# TM4C129ENCPDT register map
File version: 1.0
CPU: CORTEX_M4 1.0, other endian, MPU, FPU, 3 interrupt priority bits
Registers are 32-bit, read-write, reset 0x0 unless marked. A register's access mark holds for its fields unless they carry their own. Offsets are from the block's base; [hi:lo] are bit positions; <NAME> marks a mode.

## UART0 — UART register offsets
Base 0x4000C000
Same registers: UART1 0x4000D000, UART2 0x4000E000, UART3 0x4000F000, UART4 0x40010000, UART5 0x40011000, UART6 0x40012000, UART7 0x40013000
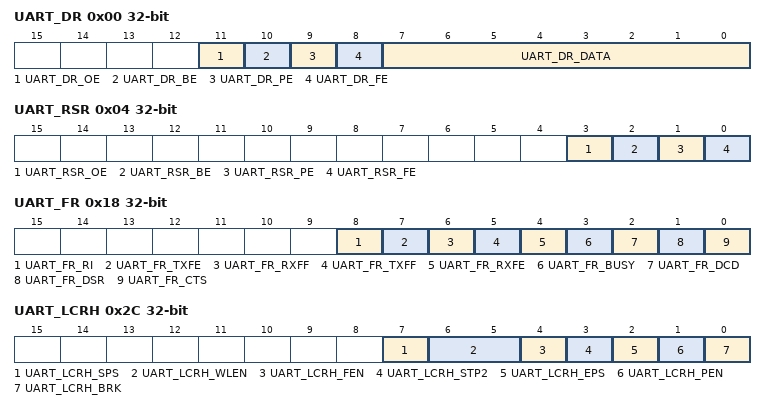
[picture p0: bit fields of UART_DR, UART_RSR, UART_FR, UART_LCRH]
0x00 UART_DR — UART Data
  [11] UART_DR_OE — [11:11] UART Overrun Error
  [10] UART_DR_BE — [10:10] UART Break Error
  [9] UART_DR_PE — [9:9] UART Parity Error
  [8] UART_DR_FE — [8:8] UART Framing Error
  [7:0] UART_DR_DATA — [7:0] Data Transmitted or Received
0x04 UART_RSR — UART Receive Status/Error Clear
  [3] UART_RSR_OE — [3:3] UART Overrun Error
  [2] UART_RSR_BE — [2:2] UART Break Error
  [1] UART_RSR_PE — [1:1] UART Parity Error
  [0] UART_RSR_FE — [0:0] UART Framing Error
0x04 UART_ECR — UART Receive Status/Error Clear
  [7:0] UART_ECR_DATA — [7:0] Error Clear
0x18 UART_FR — UART Flag
  [8] UART_FR_RI — [8:8] Ring Indicator
  [7] UART_FR_TXFE — [7:7] UART Transmit FIFO Empty
  [6] UART_FR_RXFF — [6:6] UART Receive FIFO Full
  [5] UART_FR_TXFF — [5:5] UART Transmit FIFO Full
  [4] UART_FR_RXFE — [4:4] UART Receive FIFO Empty
  [3] UART_FR_BUSY — [3:3] UART Busy
  [2] UART_FR_DCD — [2:2] Data Carrier Detect
  [1] UART_FR_DSR — [1:1] Data Set Ready
  [0] UART_FR_CTS — [0:0] Clear To Send
0x20 UART_ILPR — UART IrDA Low-Power Register
  [7:0] UART_ILPR_ILPDVSR — [7:0] IrDA Low-Power Divisor
0x24 UART_IBRD — UART Integer Baud-Rate Divisor
  [15:0] UART_IBRD_DIVINT — [15:0] Integer Baud-Rate Divisor
0x28 UART_FBRD — UART Fractional Baud-Rate Divisor
  [5:0] UART_FBRD_DIVFRAC — [5:0] Fractional Baud-Rate Divisor
0x2C UART_LCRH — UART Line Control
  [7] UART_LCRH_SPS — [7:7] UART Stick Parity Select
  [6:5] UART_LCRH_WLEN — [6:5] UART Word Length
    0=5 bits (default); 32=6 bits; 64=7 bits; 96=8 bits
  [4] UART_LCRH_FEN — [4:4] UART Enable FIFOs
  [3] UART_LCRH_STP2 — [3:3] UART Two Stop Bits Select
  [2] UART_LCRH_EPS — [2:2] UART Even Parity Select
  [1] UART_LCRH_PEN — [1:1] UART Parity Enable
  [0] UART_LCRH_BRK — [0:0] UART Send Break
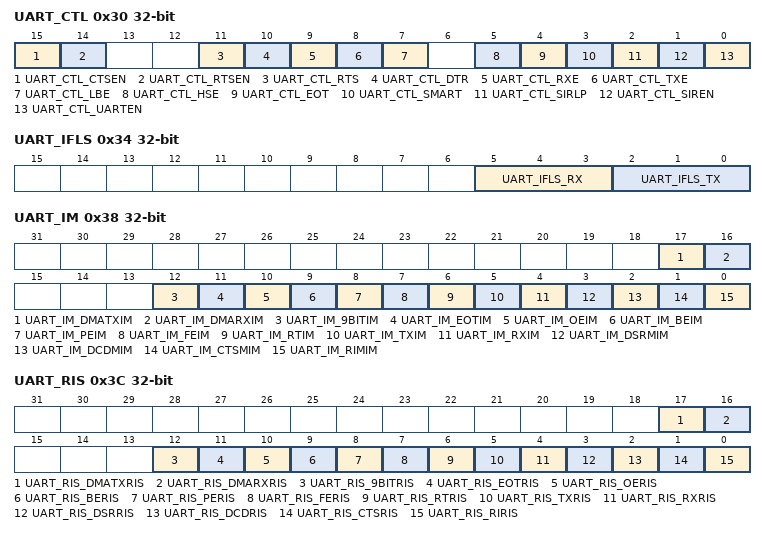
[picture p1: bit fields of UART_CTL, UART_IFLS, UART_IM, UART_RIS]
0x30 UART_CTL — UART Control
  [15] UART_CTL_CTSEN — [15:15] Enable Clear To Send
  [14] UART_CTL_RTSEN — [14:14] Enable Request to Send
  [11] UART_CTL_RTS — [11:11] Request to Send
  [10] UART_CTL_DTR — [10:10] Data Terminal Ready
  [9] UART_CTL_RXE — [9:9] UART Receive Enable
  [8] UART_CTL_TXE — [8:8] UART Transmit Enable
  [7] UART_CTL_LBE — [7:7] UART Loop Back Enable
  [5] UART_CTL_HSE — [5:5] High-Speed Enable
  [4] UART_CTL_EOT — [4:4] End of Transmission
  [3] UART_CTL_SMART — [3:3] ISO 7816 Smart Card Support
  [2] UART_CTL_SIRLP — [2:2] UART SIR Low-Power Mode
  [1] UART_CTL_SIREN — [1:1] UART SIR Enable
  [0] UART_CTL_UARTEN — [0:0] UART Enable
0x34 UART_IFLS — UART Interrupt FIFO Level Select
  [5:3] UART_IFLS_RX — [5:3] UART Receive Interrupt FIFO Level Select
    0=UART_IFLS_RX1_8 (RX FIFO >= 1/8 full); 8=UART_IFLS_RX2_8 (RX FIFO >= 1/4 full); 16=UART_IFLS_RX4_8 (RX FIFO >= 1/2 full (default)); 24=UART_IFLS_RX6_8 (RX FIFO >= 3/4 full); 32=UART_IFLS_RX7_8 (RX FIFO >= 7/8 full)
  [2:0] UART_IFLS_TX — [2:0] UART Transmit Interrupt FIFO Level Select
    0=UART_IFLS_TX1_8 (TX FIFO <= 1/8 full); 1=UART_IFLS_TX2_8 (TX FIFO <= 1/4 full); 2=UART_IFLS_TX4_8 (TX FIFO <= 1/2 full (default)); 3=UART_IFLS_TX6_8 (TX FIFO <= 3/4 full); 4=UART_IFLS_TX7_8 (TX FIFO <= 7/8 full)
0x38 UART_IM — UART Interrupt Mask
  [17] UART_IM_DMATXIM — [17:17] Transmit DMA Interrupt Mask
  [16] UART_IM_DMARXIM — [16:16] Receive DMA Interrupt Mask
  [12] UART_IM_9BITIM — [12:12] 9-Bit Mode Interrupt Mask
  [11] UART_IM_EOTIM — [11:11] End of Transmission Interrupt Mask
  [10] UART_IM_OEIM — [10:10] UART Overrun Error Interrupt Mask
  [9] UART_IM_BEIM — [9:9] UART Break Error Interrupt Mask
  [8] UART_IM_PEIM — [8:8] UART Parity Error Interrupt Mask
  [7] UART_IM_FEIM — [7:7] UART Framing Error Interrupt Mask
  [6] UART_IM_RTIM — [6:6] UART Receive Time-Out Interrupt Mask
  [5] UART_IM_TXIM — [5:5] UART Transmit Interrupt Mask
  [4] UART_IM_RXIM — [4:4] UART Receive Interrupt Mask
  [3] UART_IM_DSRMIM — [3:3] UART Data Set Ready Modem Interrupt Mask
  [2] UART_IM_DCDMIM — [2:2] UART Data Carrier Detect Modem Interrupt Mask
  [1] UART_IM_CTSMIM — [1:1] UART Clear to Send Modem Interrupt Mask
  [0] UART_IM_RIMIM — [0:0] UART Ring Indicator Modem Interrupt Mask
0x3C UART_RIS — UART Raw Interrupt Status
  [17] UART_RIS_DMATXRIS — [17:17] Transmit DMA Raw Interrupt Status
  [16] UART_RIS_DMARXRIS — [16:16] Receive DMA Raw Interrupt Status
  [12] UART_RIS_9BITRIS — [12:12] 9-Bit Mode Raw Interrupt Status
  [11] UART_RIS_EOTRIS — [11:11] End of Transmission Raw Interrupt Status
  [10] UART_RIS_OERIS — [10:10] UART Overrun Error Raw Interrupt Status
  [9] UART_RIS_BERIS — [9:9] UART Break Error Raw Interrupt Status
  [8] UART_RIS_PERIS — [8:8] UART Parity Error Raw Interrupt Status
  [7] UART_RIS_FERIS — [7:7] UART Framing Error Raw Interrupt Status
  [6] UART_RIS_RTRIS — [6:6] UART Receive Time-Out Raw Interrupt Status
  [5] UART_RIS_TXRIS — [5:5] UART Transmit Raw Interrupt Status
  [4] UART_RIS_RXRIS — [4:4] UART Receive Raw Interrupt Status
  [3] UART_RIS_DSRRIS — [3:3] UART Data Set Ready Modem Raw Interrupt Status
  [2] UART_RIS_DCDRIS — [2:2] UART Data Carrier Detect Modem Raw Interrupt Status
  [1] UART_RIS_CTSRIS — [1:1] UART Clear to Send Modem Raw Interrupt Status
  [0] UART_RIS_RIRIS — [0:0] UART Ring Indicator Modem Raw Interrupt Status
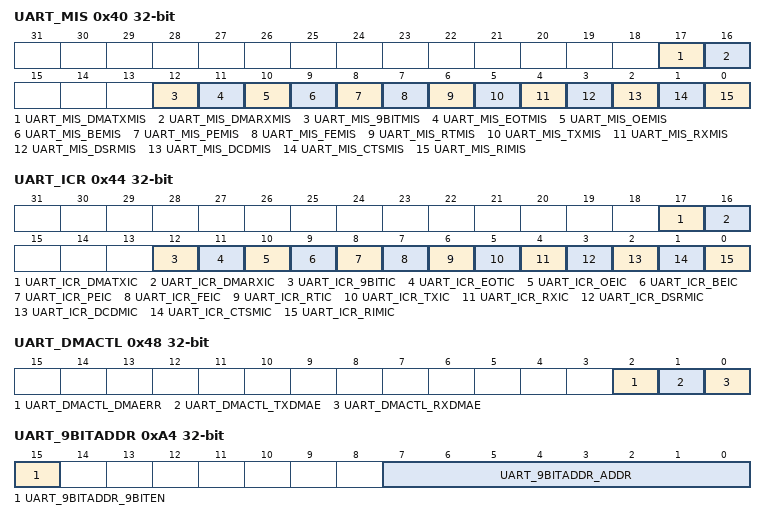
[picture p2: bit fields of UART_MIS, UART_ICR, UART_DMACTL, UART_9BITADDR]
0x40 UART_MIS — UART Masked Interrupt Status
  [17] UART_MIS_DMATXMIS — [17:17] Transmit DMA Masked Interrupt Status
  [16] UART_MIS_DMARXMIS — [16:16] Receive DMA Masked Interrupt Status
  [12] UART_MIS_9BITMIS — [12:12] 9-Bit Mode Masked Interrupt Status
  [11] UART_MIS_EOTMIS — [11:11] End of Transmission Masked Interrupt Status
  [10] UART_MIS_OEMIS — [10:10] UART Overrun Error Masked Interrupt Status
  [9] UART_MIS_BEMIS — [9:9] UART Break Error Masked Interrupt Status
  [8] UART_MIS_PEMIS — [8:8] UART Parity Error Masked Interrupt Status
  [7] UART_MIS_FEMIS — [7:7] UART Framing Error Masked Interrupt Status
  [6] UART_MIS_RTMIS — [6:6] UART Receive Time-Out Masked Interrupt Status
  [5] UART_MIS_TXMIS — [5:5] UART Transmit Masked Interrupt Status
  [4] UART_MIS_RXMIS — [4:4] UART Receive Masked Interrupt Status
  [3] UART_MIS_DSRMIS — [3:3] UART Data Set Ready Modem Masked Interrupt Status
  [2] UART_MIS_DCDMIS — [2:2] UART Data Carrier Detect Modem Masked Interrupt Status
  [1] UART_MIS_CTSMIS — [1:1] UART Clear to Send Modem Masked Interrupt Status
  [0] UART_MIS_RIMIS — [0:0] UART Ring Indicator Modem Masked Interrupt Status
0x44 UART_ICR — UART Interrupt Clear
  [17] UART_ICR_DMATXIC — [17:17] Transmit DMA Interrupt Clear
  [16] UART_ICR_DMARXIC — [16:16] Receive DMA Interrupt Clear
  [12] UART_ICR_9BITIC — [12:12] 9-Bit Mode Interrupt Clear
  [11] UART_ICR_EOTIC — [11:11] End of Transmission Interrupt Clear
  [10] UART_ICR_OEIC — [10:10] Overrun Error Interrupt Clear
  [9] UART_ICR_BEIC — [9:9] Break Error Interrupt Clear
  [8] UART_ICR_PEIC — [8:8] Parity Error Interrupt Clear
  [7] UART_ICR_FEIC — [7:7] Framing Error Interrupt Clear
  [6] UART_ICR_RTIC — [6:6] Receive Time-Out Interrupt Clear
  [5] UART_ICR_TXIC — [5:5] Transmit Interrupt Clear
  [4] UART_ICR_RXIC — [4:4] Receive Interrupt Clear
  [3] UART_ICR_DSRMIC — [3:3] UART Data Set Ready Modem Interrupt Clear
  [2] UART_ICR_DCDMIC — [2:2] UART Data Carrier Detect Modem Interrupt Clear
  [1] UART_ICR_CTSMIC — [1:1] UART Clear to Send Modem Interrupt Clear
  [0] UART_ICR_RIMIC — [0:0] UART Ring Indicator Modem Interrupt Clear
0x48 UART_DMACTL — UART DMA Control
  [2] UART_DMACTL_DMAERR — [2:2] DMA on Error
  [1] UART_DMACTL_TXDMAE — [1:1] Transmit DMA Enable
  [0] UART_DMACTL_RXDMAE — [0:0] Receive DMA Enable
0xA4 UART_9BITADDR — UART 9-Bit Self Address
  [15] UART_9BITADDR_9BITEN — [15:15] Enable 9-Bit Mode
  [7:0] UART_9BITADDR_ADDR — [7:0] Self Address for 9-Bit Mode
0xA8 UART_9BITAMASK — UART 9-Bit Self Address Mask
  [7:0] UART_9BITAMASK_MASK — [7:0] Self Address Mask for 9-Bit Mode
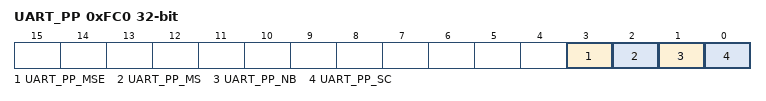
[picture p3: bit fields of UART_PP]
0xFC0 UART_PP — UART Peripheral Properties
  [3] UART_PP_MSE — [3:3] Modem Support Extended
  [2] UART_PP_MS — [2:2] Modem Support
  [1] UART_PP_NB — [1:1] 9-Bit Support
  [0] UART_PP_SC — [0:0] Smart Card Support
0xFC8 UART_CC — UART Clock Configuration
  [3:0] UART_CC_CS — [3:0] UART Baud Clock Source
    0=UART_CC_CS_SYSCLK (System clock (based on clock source and divisor factor)); 5=UART_CC_CS_PIOSC (PIOSC)
